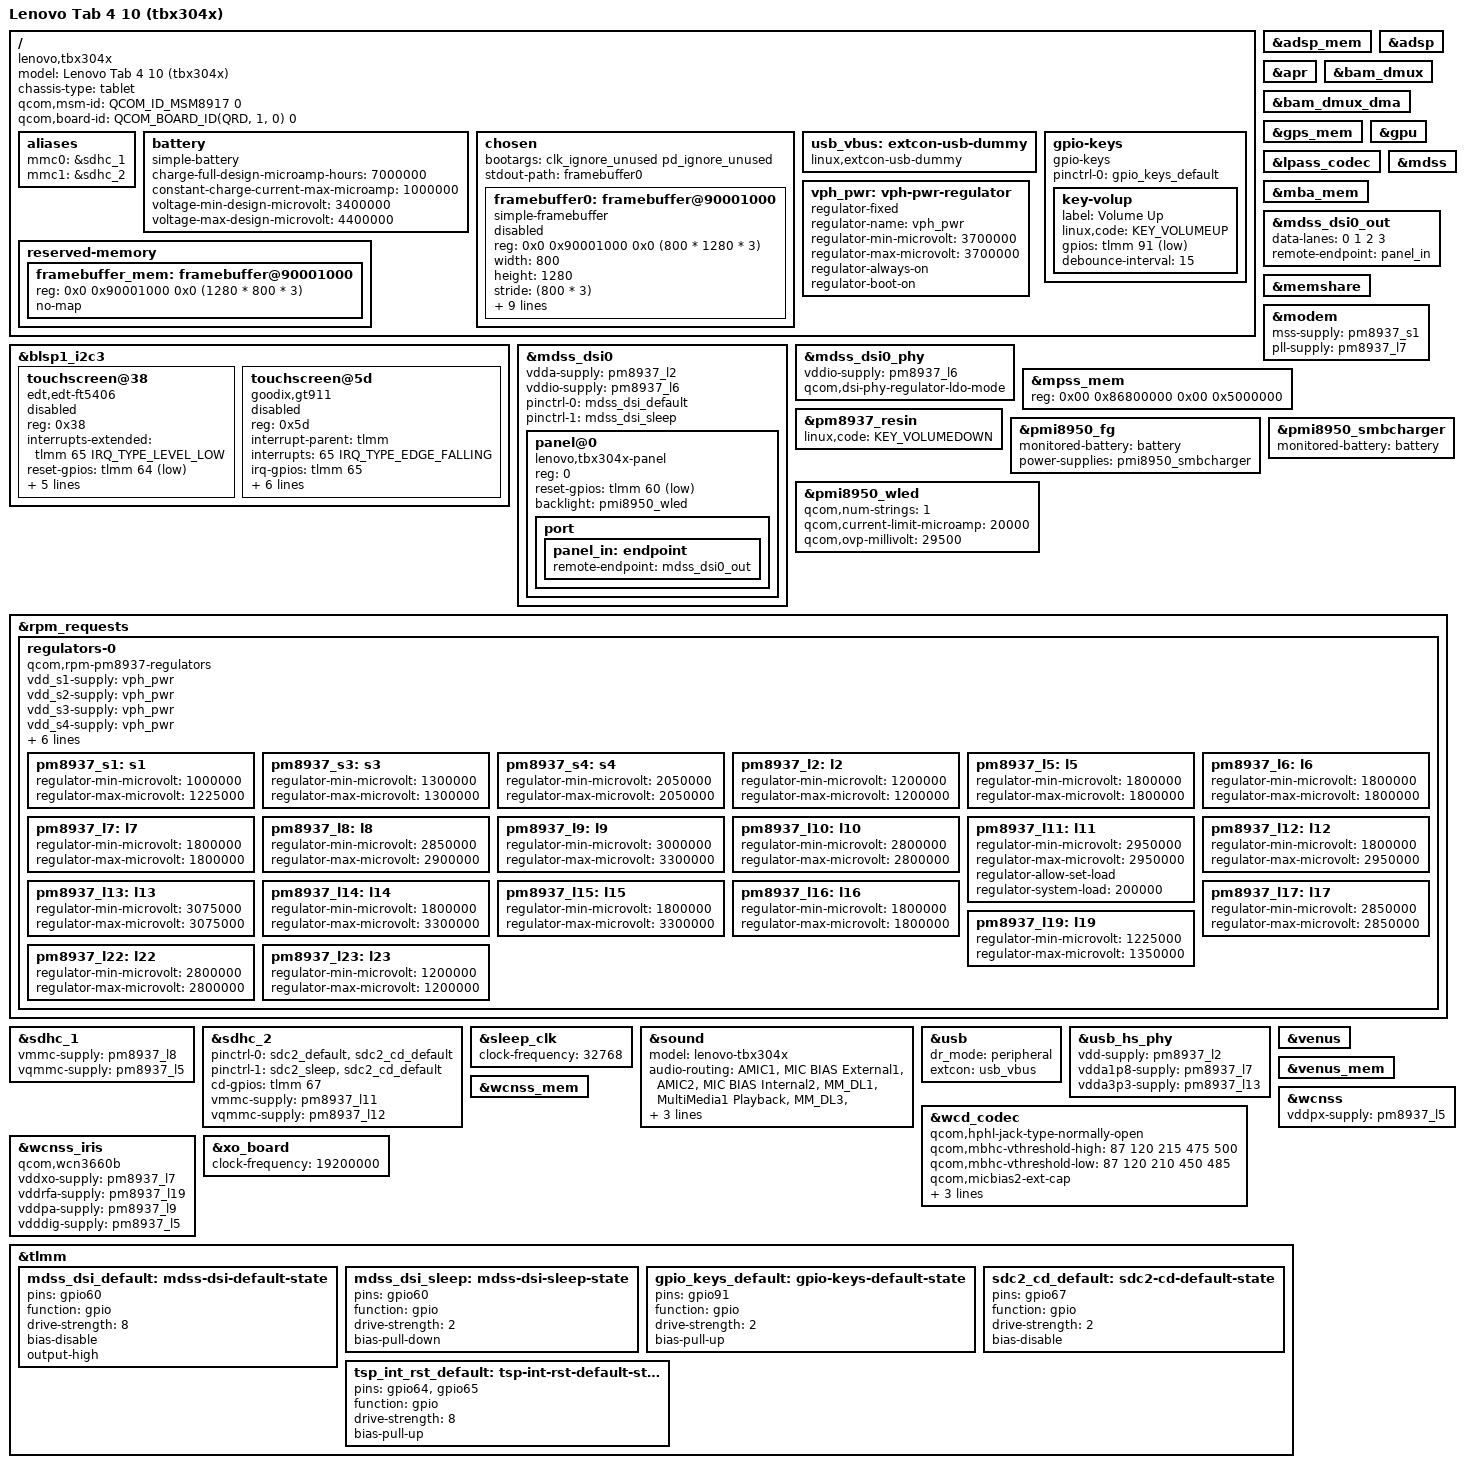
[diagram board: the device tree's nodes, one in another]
// SPDX-License-Identifier: GPL-2.0
/*
 * Copyright (c) 2025, ahi6
 * Copyright (c) 2026, Glebenekt
 */

/dts-v1/;

#include <dt-bindings/arm/qcom,ids.h>
#include <dt-bindings/gpio/gpio.h>
#include "msm8917.dtsi"
#include "pm8937.dtsi"
#include "pmi8950.dtsi"
#include "msm8937-qdsp6.dtsi"

// /delete-node/ &qseecom_mem;

/ {
	model = "Lenovo Tab 4 10 (tbx304x)";
	compatible = "lenovo,tbx304x", "qcom,msm8917";
	chassis-type = "tablet";

	qcom,msm-id = <QCOM_ID_MSM8917 0>;
	qcom,board-id = <QCOM_BOARD_ID(QRD, 1, 0) 0>;

	aliases {
		mmc0 = &sdhc_1;
		mmc1 = &sdhc_2;
	};

	battery: battery {
		compatible = "simple-battery";
		charge-full-design-microamp-hours = <7000000>;
		constant-charge-current-max-microamp = <1000000>;
		voltage-min-design-microvolt = <3400000>;
		voltage-max-design-microvolt = <4400000>;
	};

	chosen {
		#address-cells = <2>;
		#size-cells = <2>;
		ranges;

		bootargs = "clk_ignore_unused pd_ignore_unused";
		stdout-path = "framebuffer0";

		framebuffer0: framebuffer@90001000 {
			compatible = "simple-framebuffer";
			reg = <0x0 0x90001000 0x0 (800 * 1280 * 3)>;
			width = <800>;
			height = <1280>;
			stride = <(800 * 3)>;
			format = "r8g8b8";

			clocks = <&gcc GCC_MDSS_AHB_CLK>,
			<&gcc GCC_MDSS_AXI_CLK>,
			<&gcc GCC_MDSS_VSYNC_CLK>,
			<&gcc GCC_MDSS_MDP_CLK>,
			<&gcc GCC_MDSS_BYTE0_CLK>,
			<&gcc GCC_MDSS_PCLK0_CLK>,
			<&gcc GCC_MDSS_ESC0_CLK>;
			power-domains = <&gcc MDSS_GDSC>;

			status = "disabled";
		};
	};

	usb_vbus: extcon-usb-dummy {
		compatible = "linux,extcon-usb-dummy";
	};


	gpio-keys {
		compatible = "gpio-keys";

		pinctrl-0 = <&gpio_keys_default>;
		pinctrl-names = "default";

		key-volup {
			label = "Volume Up";
			linux,code = <KEY_VOLUMEUP>;
			gpios = <&tlmm 91 GPIO_ACTIVE_LOW>;
			debounce-interval = <15>;
		};
	};

	reserved-memory {
		framebuffer_mem: framebuffer@90001000 {
		reg = <0x0 0x90001000 0x0 (1280 * 800 * 3)>;
		no-map;
		};

        /*
         *		// maybe handled by lk2nd?
         *		ramoops_mem: ramoops@0x8ee00000 {
         *			compatible = "ramoops";
         *			reg = <0x0 0x8ee00000 0x0 0x80000>;
         *			console-size = <0x40000>;
    };
    */
	};


	vph_pwr: vph-pwr-regulator {
		compatible = "regulator-fixed";
		regulator-name = "vph_pwr";
		regulator-min-microvolt = <3700000>;
		regulator-max-microvolt = <3700000>;
		regulator-always-on;
		regulator-boot-on;
	};

};

&adsp_mem {
	status = "okay";
};

&adsp {
	status = "okay";
};

&apr {
	status = "okay";
};

//Bus Access Manager Data Multiplexer
&bam_dmux {
	status = "okay";
};

&bam_dmux_dma {
	status = "okay";
};

//&blsp1_i2c2 TODO


&blsp1_i2c3 {
	status = "okay";


	touchscreen@38 {
		compatible = "edt,edt-ft5406";
		reg = <0x38>;
		interrupts-extended = <&tlmm 65 IRQ_TYPE_LEVEL_LOW>;
		reset-gpios = <&tlmm 64 GPIO_ACTIVE_LOW>;
		pinctrl-0 = <&tsp_int_rst_default>;
		pinctrl-names = "default";
		vcc-supply = <&pm8937_l10>;
		iovcc-supply = <&pm8937_l5>;
		touchscreen-size-x = <800>;
		touchscreen-size-y = <1280>;

		status = "disabled";
	};

	touchscreen@5d {
		compatible = "goodix,gt911";
		reg = <0x5d>;
		interrupt-parent = <&tlmm>;
		interrupts = <65 IRQ_TYPE_EDGE_FALLING>;
		irq-gpios = <&tlmm 65 GPIO_ACTIVE_HIGH>;
		reset-gpios = <&tlmm 64 GPIO_ACTIVE_HIGH>;
		AVDD28-supply = <&pm8937_l10>;
		VDDIO-supply = <&pm8937_l6>;

		pinctrl-0 = <&tsp_int_rst_default>;
		pinctrl-names = "default";

		touchscreen-size-x = <800>;
		touchscreen-size-y = <1280>;

		status = "disabled";
	};

};

//enabled gps
&gps_mem {
	status = "okay";
};

//enabled gpu
&gpu {
	status = "okay";
};

//Low-Power Audio Subsystem
&lpass_codec{
	status = "okay";
};

&mba_mem {
	status = "okay";
};

// display subsystem
&mdss {
	status = "okay";
};

//add panel
&mdss_dsi0 {
	vdda-supply = <&pm8937_l2>;
	vddio-supply = <&pm8937_l6>;

	pinctrl-0 = <&mdss_dsi_default>;
	pinctrl-1 = <&mdss_dsi_sleep>;
	pinctrl-names = "default", "sleep";

	panel@0 {
		compatible = "lenovo,tbx304x-panel";
		reg = <0>;

		reset-gpios = <&tlmm 60 GPIO_ACTIVE_LOW>;

		backlight = <&pmi8950_wled>;

		port {
			panel_in: endpoint {
			remote-endpoint = <&mdss_dsi0_out>;
			};
		};
	};
};

&mdss_dsi0_out {
	data-lanes = <0 1 2 3>;
	remote-endpoint = <&panel_in>;
};

&mdss_dsi0_phy {
	vddio-supply = <&pm8937_l6>;
	qcom,dsi-phy-regulator-ldo-mode;
};


&memshare {
	status = "okay";
};

&modem {
	mss-supply = <&pm8937_s1>;
	pll-supply = <&pm8937_l7>;
	status = "okay";
};


&mpss_mem {
	reg = <0x00 0x86800000 0x00 0x5000000>;
	status = "okay";
};

//add vol down
&pm8937_resin {
	linux,code = <KEY_VOLUMEDOWN>;
	status = "okay";
};

&pmi8950_fg {
	monitored-battery = <&battery>;
	power-supplies = <&pmi8950_smbcharger>;
	status = "okay";
};

&pmi8950_smbcharger {
	monitored-battery = <&battery>;
	status = "okay";
};

&pmi8950_wled {
	qcom,num-strings = <1>;
	qcom,current-limit-microamp = <20000>;
	qcom,ovp-millivolt = <29500>;

	status = "okay";
};

&rpm_requests {
	regulators-0 {
		compatible = "qcom,rpm-pm8937-regulators";

		vdd_s1-supply = <&vph_pwr>;
		vdd_s2-supply = <&vph_pwr>;
		vdd_s3-supply = <&vph_pwr>;
		vdd_s4-supply = <&vph_pwr>;

		vdd_l1_l19-supply = <&pm8937_s3>;
		vdd_l2_l23-supply = <&pm8937_s3>;
		vdd_l3-supply = <&pm8937_s3>;
		vdd_l4_l5_l6_l7_l16-supply = <&pm8937_s4>;
		vdd_l8_l11_l12_l17_l22-supply = <&vph_pwr>;
		vdd_l9_l10_l13_l14_l15_l18-supply = <&vph_pwr>;

		// correct
		// MSM Modem
		pm8937_s1: s1 {
			regulator-min-microvolt = <1000000>;
			regulator-max-microvolt = <1225000>;
		};

/*
*		// DO NOT ENABLE, differs in downstream
*		// Core CPU, graphics
*		pm8937_s2: s2 {
*			regulator-min-microvolt = <550000>;
*			regulator-max-microvolt = <1350000>;
*		};
*/

		// correct
		// 1,2,3,18,23 LDOs
		pm8937_s3: s3 {
			regulator-min-microvolt = <1300000>;
			regulator-max-microvolt = <1300000>;
		};

		// correct
		// 4,5,6,7,16 LDOs; RF,XO clocks
		pm8937_s4: s4 {
			regulator-min-microvolt = <2050000>;
			regulator-max-microvolt = <2050000>;
		};

		// l1 not present in downstream

		// correct
		pm8937_l2: l2 {
			regulator-min-microvolt = <1200000>;
			regulator-max-microvolt = <1200000>;
		};

		// l3 present, hopefully unimportant; managed as a power domain => no way to set a dangerous voltage
		// l4 missing

		// correct
		// some io, eMMC, among other things
		pm8937_l5: l5 {
			regulator-min-microvolt = <1800000>;
			regulator-max-microvolt = <1800000>;
		};

		// correct
		// display, touchscreen, cam
		pm8937_l6: l6 {
			regulator-min-microvolt = <1800000>;
			regulator-max-microvolt = <1800000>;
		};

		// correct
		pm8937_l7: l7 {
			regulator-min-microvolt = <1800000>;
			regulator-max-microvolt = <1800000>;
		};

		// correct
		// eMMC
		pm8937_l8: l8 {
			regulator-min-microvolt = <2850000>;
			regulator-max-microvolt = <2900000>;
		};

		// correct
		pm8937_l9: l9 {
			regulator-min-microvolt = <3000000>;
			regulator-max-microvolt = <3300000>;
		};

		// i think max-mV should be set to 2_900_000, but it'll work fine i hope
		// in DS it's set to 3_000_000 lol
		pm8937_l10: l10 {
			regulator-min-microvolt = <2800000>;
			regulator-max-microvolt = <2800000>;
		};

		// mV is correct
		// idk how to check the load vals, let's just trust them
		// allegedly the load vals increase SD card stability
		// SD card
		pm8937_l11: l11 {
			regulator-min-microvolt = <2950000>;
			regulator-max-microvolt = <2950000>;
			regulator-allow-set-load;
			regulator-system-load = <200000>;
		};

		// weird but correct
		pm8937_l12: l12 {
			regulator-min-microvolt = <1800000>;
			regulator-max-microvolt = <2950000>;
		};

		// correct
		// usb, maybe sound as well
		pm8937_l13: l13 {
			regulator-min-microvolt = <3075000>;
			regulator-max-microvolt = <3075000>;
		};

		// correct
		pm8937_l14: l14 {
			regulator-min-microvolt = <1800000>;
			regulator-max-microvolt = <3300000>;
		};

		// correct
		pm8937_l15: l15 {
			regulator-min-microvolt = <1800000>;
			regulator-max-microvolt = <3300000>;
		};

		// correct
		pm8937_l16: l16 {
			regulator-min-microvolt = <1800000>;
			regulator-max-microvolt = <1800000>;
		};

		// downstream has this min 2_800_000 -> max 2_900_000
		// correct
		// display, touchscreen, cam
		pm8937_l17: l17 {
			regulator-min-microvolt = <2850000>;
			regulator-max-microvolt = <2850000>;
		};

/*
*		// MISSING IN DOWNSTREAM
*		// uh-oh
*		// disabling it
*		pm8937_l18: l18 {
*			regulator-min-microvolt = <2700000>;
*			regulator-max-microvolt = <2700000>;
*		};
*/

		// correct, probably
		pm8937_l19: l19 {
			regulator-min-microvolt = <1225000>;
			regulator-max-microvolt = <1350000>;
		};

		// incorrect, downstream has this at 2_800_000
		// changing it from 2_900_000
		// cam
		pm8937_l22: l22 {
			regulator-min-microvolt = <2800000>;
			regulator-max-microvolt = <2800000>;
		};

		// correct
		// cam
		pm8937_l23: l23 {
			regulator-min-microvolt = <1200000>;
			regulator-max-microvolt = <1200000>;
		};

	};

};

&sdhc_1 {
	// are these needed? doesn't look like it
	// i mean, they seem correct to me though, so i guess i'm keeping them
	vmmc-supply = <&pm8937_l8>;
	vqmmc-supply = <&pm8937_l5>;

	status = "okay";
};

&sdhc_2 {
	pinctrl-0 = <&sdc2_default &sdc2_cd_default>;
	pinctrl-1 = <&sdc2_sleep &sdc2_cd_default>;
	pinctrl-names = "default", "sleep";

	cd-gpios = <&tlmm 67 GPIO_ACTIVE_HIGH>;

	// same goes for these ones; are they needed?
	vmmc-supply = <&pm8937_l11>;
	vqmmc-supply = <&pm8937_l12>;

	status = "okay";
};

&sleep_clk {
	clock-frequency = <32768>;
};

//add initial audio
&sound {
	model = "lenovo-tbx304x";

	audio-routing =
	"AMIC1", "MIC BIAS External1",
	"AMIC2", "MIC BIAS Internal2",
	"MM_DL1", "MultiMedia1 Playback",
	"MM_DL3", "MultiMedia3 Playback",
	"MM_DL4", "MultiMedia4 Playback",
	"MultiMedia2 Capture", "MM_UL2";

	status = "okay";
};


//usb
&usb {
	dr_mode = "peripheral";
	extcon = <&usb_vbus>;
	status = "okay";
};

&usb_hs_phy {
	vdd-supply = <&pm8937_l2>;
	vdda1p8-supply = <&pm8937_l7>;
	vdda3p3-supply = <&pm8937_l13>;
	status = "okay";
};

//add venus(hw decode)
&venus {
	status = "okay";
};

&venus_mem {
	status = "okay";
};

//add wcd
&wcd_codec {
	qcom,hphl-jack-type-normally-open;
	qcom,mbhc-vthreshold-high = <87 120 215 475 500>;
	qcom,mbhc-vthreshold-low = <87 120 210 450 485>;
	qcom,micbias2-ext-cap;

	vdd-cdc-io-supply = <&pm8937_l5>;
	vdd-cdc-tx-rx-cx-supply = <&pm8937_s4>;
	vdd-micbias-supply = <&pm8937_l13>;
	status = "okay";
};


//add wifi
&wcnss {
	vddpx-supply = <&pm8937_l5>;
	status = "okay";
};

&wcnss_iris {
	compatible = "qcom,wcn3660b";
	vddxo-supply = <&pm8937_l7>;
	vddrfa-supply = <&pm8937_l19>;
	vddpa-supply = <&pm8937_l9>;
	vdddig-supply = <&pm8937_l5>;
};

&wcnss_mem {
	status = "okay";
};

//base clock
&xo_board {
	clock-frequency = <19200000>;
};

&tlmm {
	mdss_dsi_default: mdss-dsi-default-state {
		pins = "gpio60";
		function = "gpio";
		drive-strength = <8>;
		bias-disable;
		output-high;
	};

	mdss_dsi_sleep: mdss-dsi-sleep-state {
		pins = "gpio60";
		function = "gpio";
		drive-strength = <2>;
		bias-pull-down;
	};

	gpio_keys_default: gpio-keys-default-state {
		pins = "gpio91";
		function = "gpio";
		drive-strength = <2>;
		bias-pull-up;
	};

	sdc2_cd_default: sdc2-cd-default-state {
		pins = "gpio67";
		function = "gpio";
		drive-strength = <2>;
		bias-disable;
	};

	tsp_int_rst_default: tsp-int-rst-default-state {
		pins = "gpio64", "gpio65";
		function = "gpio";
		drive-strength = <8>;
		bias-pull-up;
	};

};
